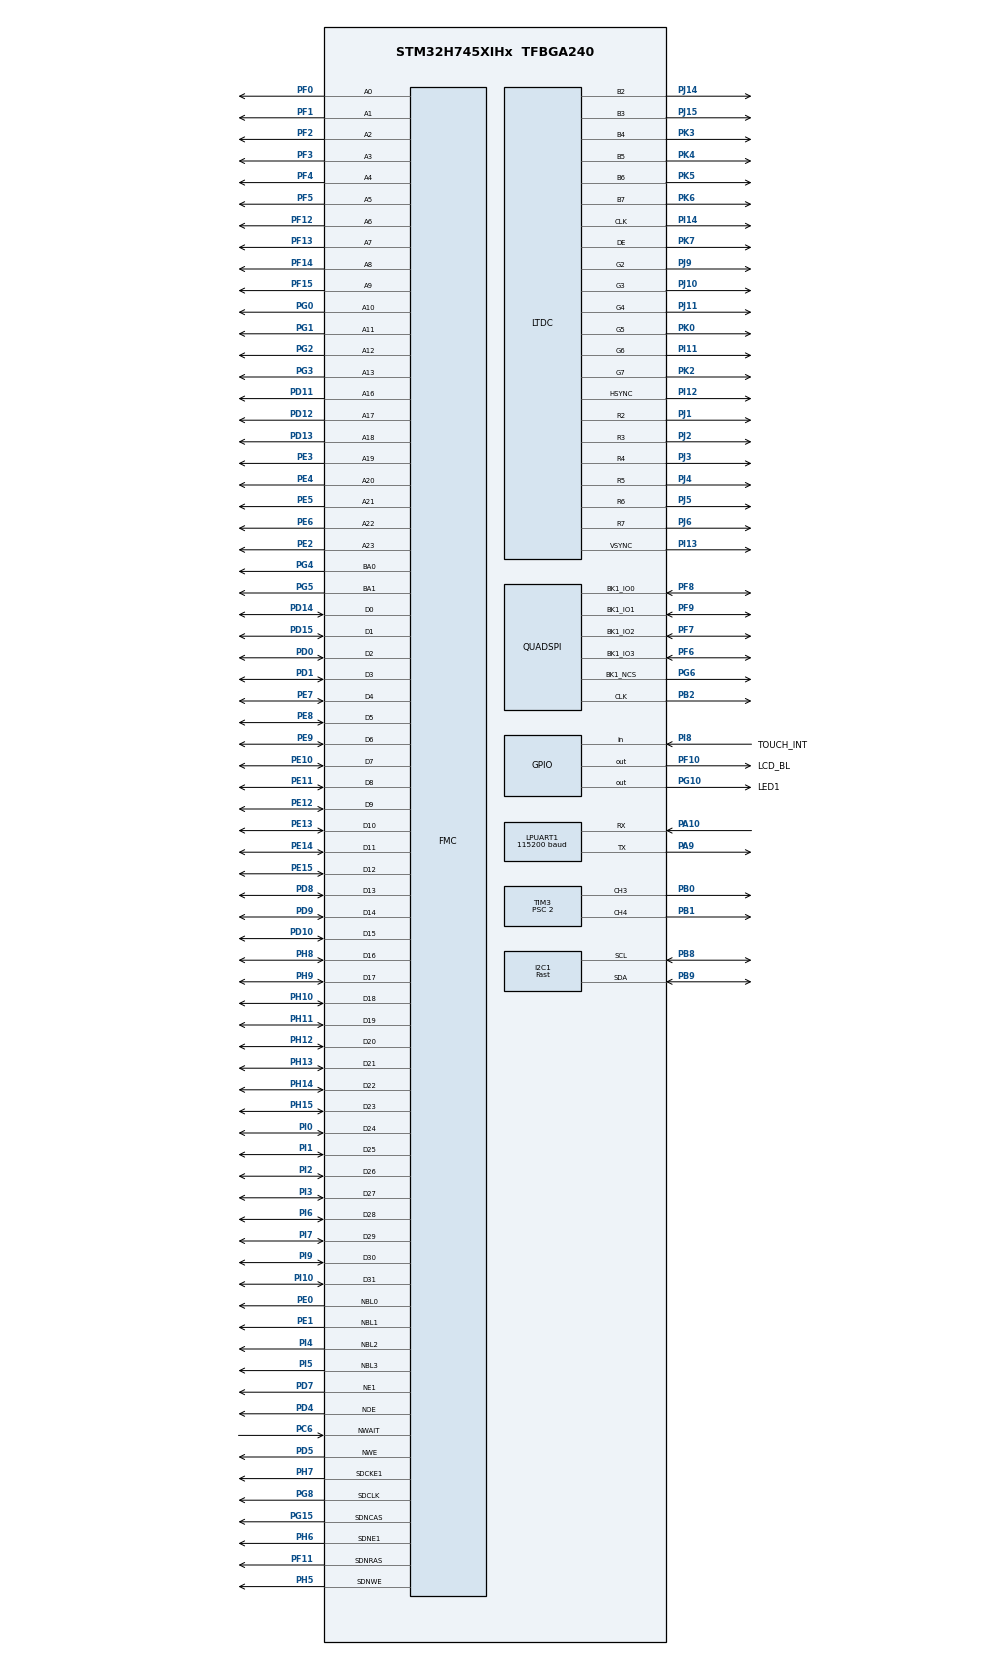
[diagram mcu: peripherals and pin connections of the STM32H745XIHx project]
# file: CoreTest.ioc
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CORTEX_M7.CPU_DCache=Enabled
CORTEX_M7.CPU_ICache=Enabled
CortexM4.IPs=CORTEX_M4\:I,DEBUG,FATFS_M4\:I,FREERTOS_M4\:I,IWDG2\:I,OPENAMP_M4\:I,PDM2PCM_M4\:I,PWR,RCC,RESMGR_UTILITY,SYS_M4\:I,USB_DEVICE_M4\:I,USB_HOST_M4\:I,VREFBUF,WWDG2\:I,DMA,BDMA,MDMA,NVIC2\:I,RTC
CortexM7.IPs=CORTEX_M7\:I,DEBUG\:I,FATFS_M7\:I,FREERTOS_M7\:I,IWDG1\:I,OPENAMP_M7\:I,PDM2PCM_M7\:I,PWR\:I,RCC\:I,RESMGR_UTILITY\:I,SYS\:I,USB_DEVICE_M7\:I,USB_HOST_M7\:I,VREFBUF\:I,WWDG1\:I,DMA\:I,BDMA\:I,MDMA\:I,NVIC1\:I,QUADSPI\:I,I2C1\:I,LPUART1\:I,LTDC\:I,FMC\:I,TIM3\:I,TIM4\:I,RTC\:I,DMA2D\:I
CortexM7.Pins=PG10,PI8,PF10
Dma.Request0=TIM4_CH1
Dma.Request1=TIM4_CH2
Dma.TIM4_CH1.0.Direction=DMA_MEMORY_TO_PERIPH
Dma.TIM4_CH1.0.EventEnable=DISABLE
Dma.TIM4_CH1.0.FIFOMode=DMA_FIFOMODE_DISABLE
Dma.TIM4_CH1.0.Instance=DMA1_Stream0
Dma.TIM4_CH1.0.MemDataAlignment=DMA_MDATAALIGN_WORD
Dma.TIM4_CH1.0.MemInc=DMA_MINC_ENABLE
Dma.TIM4_CH1.0.Mode=DMA_CIRCULAR
Dma.TIM4_CH1.0.PeriphDataAlignment=DMA_PDATAALIGN_WORD
Dma.TIM4_CH1.0.PeriphInc=DMA_PINC_DISABLE
Dma.TIM4_CH1.0.Polarity=HAL_DMAMUX_REQ_GEN_RISING
Dma.TIM4_CH1.0.Priority=DMA_PRIORITY_HIGH
Dma.TIM4_CH1.0.RequestNumber=1
Dma.TIM4_CH1.0.SignalID=NONE
Dma.TIM4_CH1.0.SyncEnable=DISABLE
Dma.TIM4_CH1.0.SyncPolarity=HAL_DMAMUX_SYNC_NO_EVENT
Dma.TIM4_CH1.0.SyncRequestNumber=1
Dma.TIM4_CH1.0.SyncSignalID=NONE
Dma.TIM4_CH2.1.Direction=DMA_MEMORY_TO_PERIPH
Dma.TIM4_CH2.1.EventEnable=DISABLE
Dma.TIM4_CH2.1.FIFOMode=DMA_FIFOMODE_DISABLE
Dma.TIM4_CH2.1.Instance=DMA1_Stream1
Dma.TIM4_CH2.1.MemDataAlignment=DMA_MDATAALIGN_WORD
Dma.TIM4_CH2.1.MemInc=DMA_MINC_ENABLE
Dma.TIM4_CH2.1.Mode=DMA_CIRCULAR
Dma.TIM4_CH2.1.PeriphDataAlignment=DMA_PDATAALIGN_WORD
Dma.TIM4_CH2.1.PeriphInc=DMA_PINC_DISABLE
Dma.TIM4_CH2.1.Polarity=HAL_DMAMUX_REQ_GEN_RISING
Dma.TIM4_CH2.1.Priority=DMA_PRIORITY_HIGH
Dma.TIM4_CH2.1.RequestNumber=1
Dma.TIM4_CH2.1.SignalID=NONE
Dma.TIM4_CH2.1.SyncEnable=DISABLE
Dma.TIM4_CH2.1.SyncPolarity=HAL_DMAMUX_SYNC_NO_EVENT
Dma.TIM4_CH2.1.SyncRequestNumber=1
Dma.TIM4_CH2.1.SyncSignalID=NONE
FMC.AddressSetupTime1=9
FMC.BusTurnAroundDuration1=4
FMC.CASLatency1=FMC_SDRAM_CAS_LATENCY_3
FMC.ColumnBitsNumber1=FMC_SDRAM_COLUMN_BITS_NUM_9
FMC.DataSetupTime1=5
FMC.ExitSelfRefreshDelay1=7
FMC.LoadToActiveDelay1=2
FMC.RCDDelay1=2
FMC.RPDelay1=2
FMC.ReadBurst1=FMC_SDRAM_RBURST_ENABLE
FMC.ReadPipeDelay1=FMC_SDRAM_RPIPE_DELAY_0
FMC.RowCycleDelay1=7
FMC.SDClockPeriod1=FMC_SDRAM_CLOCK_PERIOD_2
FMC.SelfRefreshTime1=4
FMC.WaitSignalPolarity1=FMC_WAIT_SIGNAL_POLARITY_LOW
FMC.WriteOperation1=FMC_WRITE_OPERATION_ENABLE
FMC.WriteRecoveryTime1=4
I2C1.I2C_Speed_Mode=I2C_Fast
I2C1.Timing=0x009034B6
LPUART1.BaudRate=115200
LTDC.ActiveH=480
LTDC.ActiveW=800
LTDC.Alpha_L0=255
LTDC.BlendingFactor1_L0=LTDC_BLENDING_FACTOR1_PAxCA
LTDC.BlendingFactor2_L0=LTDC_BLENDING_FACTOR2_PAxCA
LTDC.Blue_L0=0
LTDC.DEPolarity=LTDC_DEPOLARITY_AL
LTDC.FBStartAdress_L0=0xD0000000
LTDC.Green_L0=0
LTDC.HBP=88
LTDC.HFP=40
LTDC.HSync=48
LTDC.ImageHeight_L0=480
LTDC.ImageWidth_L0=800
LTDC.Layers=0
LTDC.PixelFormat_L0=LTDC_PIXEL_FORMAT_RGB565
LTDC.Red_L0=0
LTDC.VBP=32
LTDC.VFP=13
LTDC.VSync=3
LTDC.WindowX1_L0=800
LTDC.WindowY1_L0=480
Mcu.Family=STM32H7
Mcu.Name=STM32H745XIHx
Mcu.Package=TFBGA240
NVIC1.DMA1_Stream0_IRQn=true\:1\:0\:true\:false\:true\:false\:true
NVIC1.DMA1_Stream1_IRQn=true\:1\:0\:true\:false\:true\:false\:true
NVIC1.HSEM1_IRQn=true\:0\:0\:false\:false\:true\:true\:true
NVIC1.LPUART1_IRQn=true\:3\:0\:true\:false\:true\:true\:true
NVIC1.LTDC_IRQn=true\:0\:0\:false\:false\:true\:true\:true
NVIC1.PriorityGroup=NVIC_PRIORITYGROUP_4
NVIC1.QUADSPI_IRQn=true\:1\:0\:true\:false\:true\:true\:true
NVIC1.TIM3_IRQn=true\:2\:0\:true\:false\:true\:true\:true
NVIC1.TIM4_IRQn=true\:2\:0\:true\:false\:true\:true\:true
NVIC2.HSEM2_IRQn=true\:0\:0\:false\:false\:true\:true\:true
NVIC2.PriorityGroup=NVIC_PRIORITYGROUP_4
PA10.Mode=Asynchronous
PA10.PinAttribute=CortexM7
PA10.Signal=LPUART1_RX
PA13\ (JTMS/SWDIO).Mode=Trace_Asynchronous_SW
PA13\ (JTMS/SWDIO).PinAttribute=CortexM7
PA13\ (JTMS/SWDIO).Signal=DEBUG_JTMS-SWDIO
PA14\ (JTCK/SWCLK).Mode=Trace_Asynchronous_SW
PA14\ (JTCK/SWCLK).PinAttribute=CortexM7
PA14\ (JTCK/SWCLK).Signal=DEBUG_JTCK-SWCLK
PA9.Mode=Asynchronous
PA9.PinAttribute=CortexM7
PA9.Signal=LPUART1_TX
PB0.GPIO_Speed=GPIO_SPEED_FREQ_HIGH
PB0.PinAttribute=CortexM7
PB0.Signal=S_TIM3_CH3
PB1.GPIO_Speed=GPIO_SPEED_FREQ_HIGH
PB1.PinAttribute=CortexM7
PB1.Signal=S_TIM3_CH4
PB2.GPIO_Speed=GPIO_SPEED_FREQ_VERY_HIGH
PB2.Mode=Single Bank 1
PB2.PinAttribute=CortexM7
PB2.Signal=QUADSPI_CLK
PB3\ (JTDO/TRACESWO).Mode=Trace_Asynchronous_SW
PB3\ (JTDO/TRACESWO).PinAttribute=CortexM7
PB3\ (JTDO/TRACESWO).Signal=DEBUG_JTDO-SWO
PB8.Mode=I2C
PB8.PinAttribute=CortexM7
PB8.Signal=I2C1_SCL
PB9.Mode=I2C
PB9.PinAttribute=CortexM7
PB9.Signal=I2C1_SDA
PC14-OSC32_IN\ (OSC32_IN).Mode=LSE-External-Oscillator
PC14-OSC32_IN\ (OSC32_IN).PinAttribute=CortexM7
PC14-OSC32_IN\ (OSC32_IN).Signal=RCC_OSC32_IN
PC15-OSC32_OUT\ (OSC32_OUT).Mode=LSE-External-Oscillator
PC15-OSC32_OUT\ (OSC32_OUT).PinAttribute=CortexM7
PC15-OSC32_OUT\ (OSC32_OUT).Signal=RCC_OSC32_OUT
PC6.PinAttribute=CortexM7
PC6.Signal=FMC_NWAIT
PD0.PinAttribute=CortexM7
PD0.Signal=FMC_D2_DA2
PD1.PinAttribute=CortexM7
PD1.Signal=FMC_D3_DA3
PD10.PinAttribute=CortexM7
PD10.Signal=FMC_D15_DA15
PD11.PinAttribute=CortexM7
PD11.Signal=FMC_A16_CLE
PD12.PinAttribute=CortexM7
PD12.Signal=FMC_A17_ALE
PD13.PinAttribute=CortexM7
PD13.Signal=FMC_A18
PD14.PinAttribute=CortexM7
PD14.Signal=FMC_D0_DA0
PD15.PinAttribute=CortexM7
PD15.Signal=FMC_D1_DA1
PD4.PinAttribute=CortexM7
PD4.Signal=FMC_NOE
PD5.PinAttribute=CortexM7
PD5.Signal=FMC_NWE
PD7.Mode=NorPsramChipSelect1_1
PD7.PinAttribute=CortexM7
PD7.Signal=FMC_NE1
PD8.PinAttribute=CortexM7
PD8.Signal=FMC_D13_DA13
PD9.PinAttribute=CortexM7
PD9.Signal=FMC_D14_DA14
PE0.PinAttribute=CortexM7
PE0.Signal=FMC_NBL0
PE1.PinAttribute=CortexM7
PE1.Signal=FMC_NBL1
PE10.PinAttribute=CortexM7
PE10.Signal=FMC_D7_DA7
PE11.PinAttribute=CortexM7
PE11.Signal=FMC_D8_DA8
PE12.PinAttribute=CortexM7
PE12.Signal=FMC_D9_DA9
PE13.PinAttribute=CortexM7
PE13.Signal=FMC_D10_DA10
PE14.PinAttribute=CortexM7
PE14.Signal=FMC_D11_DA11
PE15.PinAttribute=CortexM7
PE15.Signal=FMC_D12_DA12
PE2.PinAttribute=CortexM7
PE2.Signal=FMC_A23
PE3.PinAttribute=CortexM7
PE3.Signal=FMC_A19
PE4.PinAttribute=CortexM7
PE4.Signal=FMC_A20
PE5.PinAttribute=CortexM7
PE5.Signal=FMC_A21
PE6.PinAttribute=CortexM7
PE6.Signal=FMC_A22
PE7.PinAttribute=CortexM7
PE7.Signal=FMC_D4_DA4
PE8.PinAttribute=CortexM7
PE8.Signal=FMC_D5_DA5
PE9.PinAttribute=CortexM7
PE9.Signal=FMC_D6_DA6
PF0.PinAttribute=CortexM7
PF0.Signal=FMC_A0
PF1.PinAttribute=CortexM7
PF1.Signal=FMC_A1
PF10.GPIO_Label=LCD_BL
PF10.PinAttribute=CortexM7
PF10.Signal=GPIO_Output
PF11.PinAttribute=CortexM7
PF11.Signal=FMC_SDNRAS
PF12.PinAttribute=CortexM7
PF12.Signal=FMC_A6
PF13.PinAttribute=CortexM7
PF13.Signal=FMC_A7
PF14.PinAttribute=CortexM7
PF14.Signal=FMC_A8
PF15.PinAttribute=CortexM7
PF15.Signal=FMC_A9
PF2.PinAttribute=CortexM7
PF2.Signal=FMC_A2
PF3.PinAttribute=CortexM7
PF3.Signal=FMC_A3
PF4.PinAttribute=CortexM7
PF4.Signal=FMC_A4
PF5.PinAttribute=CortexM7
PF5.Signal=FMC_A5
PF6.GPIO_Speed=GPIO_SPEED_FREQ_VERY_HIGH
PF6.Mode=Single Bank 1
PF6.PinAttribute=CortexM7
PF6.Signal=QUADSPI_BK1_IO3
PF7.GPIO_Speed=GPIO_SPEED_FREQ_VERY_HIGH
PF7.Mode=Single Bank 1
PF7.PinAttribute=CortexM7
PF7.Signal=QUADSPI_BK1_IO2
PF8.GPIO_Speed=GPIO_SPEED_FREQ_VERY_HIGH
PF8.Mode=Single Bank 1
PF8.PinAttribute=CortexM7
PF8.Signal=QUADSPI_BK1_IO0
PF9.GPIO_Speed=GPIO_SPEED_FREQ_VERY_HIGH
PF9.Mode=Single Bank 1
PF9.PinAttribute=CortexM7
PF9.Signal=QUADSPI_BK1_IO1
PG0.PinAttribute=CortexM7
PG0.Signal=FMC_A10
PG1.PinAttribute=CortexM7
PG1.Signal=FMC_A11
PG10.GPIO_Label=LED1
PG10.PinAttribute=CortexM7
PG10.Signal=GPIO_Output
PG15.PinAttribute=CortexM7
PG15.Signal=FMC_SDNCAS
PG2.PinAttribute=CortexM7
PG2.Signal=FMC_A12
PG3.PinAttribute=CortexM7
PG3.Signal=FMC_A13
PG4.PinAttribute=CortexM7
PG4.Signal=FMC_A14_BA0
PG5.PinAttribute=CortexM7
PG5.Signal=FMC_A15_BA1
PG6.GPIO_Speed=GPIO_SPEED_FREQ_VERY_HIGH
PG6.Mode=Single Bank 1
PG6.PinAttribute=CortexM7
PG6.Signal=QUADSPI_BK1_NCS
PG8.PinAttribute=CortexM7
PG8.Signal=FMC_SDCLK
PH0-OSC_IN\ (PH0).Mode=HSE-External-Oscillator
PH0-OSC_IN\ (PH0).PinAttribute=CortexM7
PH0-OSC_IN\ (PH0).Signal=RCC_OSC_IN
PH1-OSC_OUT\ (PH1).Mode=HSE-External-Oscillator
PH1-OSC_OUT\ (PH1).PinAttribute=CortexM7
PH1-OSC_OUT\ (PH1).Signal=RCC_OSC_OUT
PH10.PinAttribute=CortexM7
PH10.Signal=FMC_D18
PH11.PinAttribute=CortexM7
PH11.Signal=FMC_D19
PH12.PinAttribute=CortexM7
PH12.Signal=FMC_D20
PH13.PinAttribute=CortexM7
PH13.Signal=FMC_D21
PH14.PinAttribute=CortexM7
PH14.Signal=FMC_D22
PH15.PinAttribute=CortexM7
PH15.Signal=FMC_D23
PH5.PinAttribute=CortexM7
PH5.Signal=FMC_SDNWE
PH6.Mode=SdramChipSelect2_1
PH6.PinAttribute=CortexM7
PH6.Signal=FMC_SDNE1
PH7.Mode=SdramChipSelect2_1
PH7.PinAttribute=CortexM7
PH7.Signal=FMC_SDCKE1
PH8.PinAttribute=CortexM7
PH8.Signal=FMC_D16
PH9.PinAttribute=CortexM7
PH9.Signal=FMC_D17
PI0.PinAttribute=CortexM7
PI0.Signal=FMC_D24
PI1.PinAttribute=CortexM7
PI1.Signal=FMC_D25
PI10.PinAttribute=CortexM7
PI10.Signal=FMC_D31
PI11.Mode=RGB666
PI11.PinAttribute=CortexM7
PI11.Signal=LTDC_G6
PI12.Mode=RGB666
PI12.PinAttribute=CortexM7
PI12.Signal=LTDC_HSYNC
PI13.Mode=RGB666
PI13.PinAttribute=CortexM7
PI13.Signal=LTDC_VSYNC
PI14.Mode=RGB666
PI14.PinAttribute=CortexM7
PI14.Signal=LTDC_CLK
PI2.PinAttribute=CortexM7
PI2.Signal=FMC_D26
PI3.PinAttribute=CortexM7
PI3.Signal=FMC_D27
PI4.PinAttribute=CortexM7
PI4.Signal=FMC_NBL2
PI5.PinAttribute=CortexM7
PI5.Signal=FMC_NBL3
PI6.PinAttribute=CortexM7
PI6.Signal=FMC_D28
PI7.PinAttribute=CortexM7
PI7.Signal=FMC_D29
PI8.GPIO_Label=TOUCH_INT
PI8.PinAttribute=CortexM7
PI8.Signal=GPIO_Input
PI9.PinAttribute=CortexM7
PI9.Signal=FMC_D30
PJ1.Mode=RGB666
PJ1.PinAttribute=CortexM7
PJ1.Signal=LTDC_R2
PJ10.Mode=RGB666
PJ10.PinAttribute=CortexM7
PJ10.Signal=LTDC_G3
PJ11.Mode=RGB666
PJ11.PinAttribute=CortexM7
PJ11.Signal=LTDC_G4
PJ14.Mode=RGB666
PJ14.PinAttribute=CortexM7
PJ14.Signal=LTDC_B2
PJ15.Mode=RGB666
PJ15.PinAttribute=CortexM7
PJ15.Signal=LTDC_B3
PJ2.Mode=RGB666
PJ2.PinAttribute=CortexM7
PJ2.Signal=LTDC_R3
PJ3.Mode=RGB666
PJ3.PinAttribute=CortexM7
PJ3.Signal=LTDC_R4
PJ4.Mode=RGB666
PJ4.PinAttribute=CortexM7
PJ4.Signal=LTDC_R5
PJ5.Mode=RGB666
PJ5.PinAttribute=CortexM7
PJ5.Signal=LTDC_R6
PJ6.Mode=RGB666
PJ6.PinAttribute=CortexM7
PJ6.Signal=LTDC_R7
PJ9.Mode=RGB666
PJ9.PinAttribute=CortexM7
PJ9.Signal=LTDC_G2
PK0.Mode=RGB666
PK0.PinAttribute=CortexM7
PK0.Signal=LTDC_G5
PK2.Mode=RGB666
PK2.PinAttribute=CortexM7
PK2.Signal=LTDC_G7
PK3.Mode=RGB666
PK3.PinAttribute=CortexM7
PK3.Signal=LTDC_B4
PK4.Mode=RGB666
PK4.PinAttribute=CortexM7
PK4.Signal=LTDC_B5
PK5.Mode=RGB666
PK5.PinAttribute=CortexM7
PK5.Signal=LTDC_B6
PK6.Mode=RGB666
PK6.PinAttribute=CortexM7
PK6.Signal=LTDC_B7
PK7.Mode=RGB666
PK7.PinAttribute=CortexM7
PK7.Signal=LTDC_DE
ProjectManager.HeapSize=0x200
ProjectManager.StackSize=0x400
ProjectManager.TargetToolchain=STM32CubeIDE
QUADSPI.ClockPrescaler=4
QUADSPI.FlashSize=25
QUADSPI.SampleShifting=QSPI_SAMPLE_SHIFTING_HALFCYCLE
RCC.ADCFreq_Value=400000000
RCC.APB1Freq_Value=100000000
RCC.APB2Freq_Value=100000000
RCC.APB3Freq_Value=100000000
RCC.APB4Freq_Value=100000000
RCC.CortexFreq_Value=400000000
RCC.D1PPRE=RCC_APB3_DIV2
RCC.D2PPRE1=RCC_APB1_DIV2
RCC.D2PPRE2=RCC_APB2_DIV2
RCC.D3PPRE=RCC_APB4_DIV2
RCC.DIVM1=5
RCC.DIVM2=5
RCC.DIVM3=5
RCC.DIVN1=160
RCC.DIVN2=160
RCC.DIVN3=120
RCC.DIVQ1=4
RCC.DIVR2=8
RCC.DIVR3=20
RCC.FLatency-AdvancedSettings=FLASH_LATENCY_0
RCC.FMCCLockSelection=RCC_FMCCLKSOURCE_PLL2
RCC.HCLKFreq_Value=200000000
RCC.HPRE=RCC_HCLK_DIV2
RCC.PLL1_VCI_Range-AdvancedSettings=RCC_PLL1VCIRANGE_0
RCC.PLL1_VCO_SEL-AdvancedSettings=RCC_PLL1VCOMEDIUM
RCC.PLL3FRACN=0
RCC.PLLFRACN=0
RCC.PLLSourceVirtual=RCC_PLLSOURCE_HSE
RCC.PWR_Regulator_Voltage_Scale=PWR_REGULATOR_VOLTAGE_SCALE0
RCC.QSPICLockSelection=RCC_QSPICLKSOURCE_PLL2
RCC.SYSCLKFreq_VALUE=400000000
RCC.SYSCLKSource=RCC_SYSCLKSOURCE_PLLCLK
RCC.SupplySource=PWR_LDO_SUPPLY
RCC.USBFreq_Value=200000000
SH.FMC_A0.0=FMC_A0,24b-a1
SH.FMC_A0.1=FMC_A0,12b-sda1
SH.FMC_A1.0=FMC_A1,24b-a1
SH.FMC_A1.1=FMC_A1,12b-sda1
SH.FMC_A10.0=FMC_A10,24b-a1
SH.FMC_A10.1=FMC_A10,12b-sda1
SH.FMC_A11.0=FMC_A11,24b-a1
SH.FMC_A11.1=FMC_A11,12b-sda1
SH.FMC_A12.0=FMC_A12,24b-a1
SH.FMC_A13.0=FMC_A13,24b-a1
SH.FMC_A14_BA0.0=FMC_BA0,FourSdramBanks1
SH.FMC_A14_BA0.1=FMC_A14,24b-a1
SH.FMC_A15_BA1.0=FMC_BA1,FourSdramBanks1
SH.FMC_A15_BA1.1=FMC_A15,24b-a1
SH.FMC_A16_CLE.0=FMC_A16,24b-a1
SH.FMC_A17_ALE.0=FMC_A17,24b-a1
SH.FMC_A18.0=FMC_A18,24b-a1
SH.FMC_A19.0=FMC_A19,24b-a1
SH.FMC_A2.0=FMC_A2,24b-a1
SH.FMC_A2.1=FMC_A2,12b-sda1
SH.FMC_A20.0=FMC_A20,24b-a1
SH.FMC_A21.0=FMC_A21,24b-a1
SH.FMC_A22.0=FMC_A22,24b-a1
SH.FMC_A23.0=FMC_A23,24b-a1
SH.FMC_A3.0=FMC_A3,24b-a1
SH.FMC_A3.1=FMC_A3,12b-sda1
SH.FMC_A4.0=FMC_A4,24b-a1
SH.FMC_A4.1=FMC_A4,12b-sda1
SH.FMC_A5.0=FMC_A5,24b-a1
SH.FMC_A5.1=FMC_A5,12b-sda1
SH.FMC_A6.0=FMC_A6,24b-a1
SH.FMC_A6.1=FMC_A6,12b-sda1
SH.FMC_A7.0=FMC_A7,24b-a1
SH.FMC_A7.1=FMC_A7,12b-sda1
SH.FMC_A8.0=FMC_A8,24b-a1
SH.FMC_A8.1=FMC_A8,12b-sda1
SH.FMC_A9.0=FMC_A9,24b-a1
SH.FMC_A9.1=FMC_A9,12b-sda1
SH.FMC_D0_DA0.0=FMC_D0,sd-32b-d1
SH.FMC_D0_DA0.1=FMC_D0,16b-d1
SH.FMC_D10_DA10.0=FMC_D10,sd-32b-d1
SH.FMC_D10_DA10.1=FMC_D10,16b-d1
SH.FMC_D11_DA11.0=FMC_D11,sd-32b-d1
SH.FMC_D11_DA11.1=FMC_D11,16b-d1
SH.FMC_D12_DA12.0=FMC_D12,sd-32b-d1
SH.FMC_D12_DA12.1=FMC_D12,16b-d1
SH.FMC_D13_DA13.0=FMC_D13,sd-32b-d1
SH.FMC_D13_DA13.1=FMC_D13,16b-d1
SH.FMC_D14_DA14.0=FMC_D14,sd-32b-d1
SH.FMC_D14_DA14.1=FMC_D14,16b-d1
SH.FMC_D15_DA15.0=FMC_D15,sd-32b-d1
SH.FMC_D15_DA15.1=FMC_D15,16b-d1
SH.FMC_D16.0=FMC_D16,sd-32b-d1
SH.FMC_D17.0=FMC_D17,sd-32b-d1
SH.FMC_D18.0=FMC_D18,sd-32b-d1
SH.FMC_D19.0=FMC_D19,sd-32b-d1
SH.FMC_D1_DA1.0=FMC_D1,sd-32b-d1
SH.FMC_D1_DA1.1=FMC_D1,16b-d1
SH.FMC_D20.0=FMC_D20,sd-32b-d1
SH.FMC_D21.0=FMC_D21,sd-32b-d1
SH.FMC_D22.0=FMC_D22,sd-32b-d1
SH.FMC_D23.0=FMC_D23,sd-32b-d1
SH.FMC_D24.0=FMC_D24,sd-32b-d1
SH.FMC_D25.0=FMC_D25,sd-32b-d1
SH.FMC_D26.0=FMC_D26,sd-32b-d1
SH.FMC_D27.0=FMC_D27,sd-32b-d1
SH.FMC_D28.0=FMC_D28,sd-32b-d1
SH.FMC_D29.0=FMC_D29,sd-32b-d1
SH.FMC_D2_DA2.0=FMC_D2,sd-32b-d1
SH.FMC_D2_DA2.1=FMC_D2,16b-d1
SH.FMC_D30.0=FMC_D30,sd-32b-d1
SH.FMC_D31.0=FMC_D31,sd-32b-d1
SH.FMC_D3_DA3.0=FMC_D3,sd-32b-d1
SH.FMC_D3_DA3.1=FMC_D3,16b-d1
SH.FMC_D4_DA4.0=FMC_D4,sd-32b-d1
SH.FMC_D4_DA4.1=FMC_D4,16b-d1
SH.FMC_D5_DA5.0=FMC_D5,sd-32b-d1
SH.FMC_D5_DA5.1=FMC_D5,16b-d1
SH.FMC_D6_DA6.0=FMC_D6,sd-32b-d1
SH.FMC_D6_DA6.1=FMC_D6,16b-d1
SH.FMC_D7_DA7.0=FMC_D7,sd-32b-d1
SH.FMC_D7_DA7.1=FMC_D7,16b-d1
SH.FMC_D8_DA8.0=FMC_D8,sd-32b-d1
SH.FMC_D8_DA8.1=FMC_D8,16b-d1
SH.FMC_D9_DA9.0=FMC_D9,sd-32b-d1
SH.FMC_D9_DA9.1=FMC_D9,16b-d1
SH.FMC_NBL0.0=FMC_NBL0,Sd4ByteEnable1
SH.FMC_NBL1.0=FMC_NBL1,Sd4ByteEnable1
SH.FMC_NBL2.0=FMC_NBL2,Sd4ByteEnable1
SH.FMC_NBL3.0=FMC_NBL3,Sd4ByteEnable1
SH.FMC_NOE.0=FMC_NOE,NorFlash1
SH.FMC_NWAIT.0=FMC_NWAIT,AsynchronousWait1
SH.FMC_NWE.0=FMC_NWE,NorFlash1
SH.FMC_SDCLK.0=FMC_SDCLK,12b-sda1
SH.FMC_SDNCAS.0=FMC_SDNCAS,12b-sda1
SH.FMC_SDNRAS.0=FMC_SDNRAS,12b-sda1
SH.FMC_SDNWE.0=FMC_SDNWE,12b-sda1
SH.S_TIM3_CH3.0=TIM3_CH3,PWM Generation3 CH3
SH.S_TIM3_CH4.0=TIM3_CH4,PWM Generation4 CH4
SYS.userName=SYS_M7
TIM3.AutoReloadPreload=TIM_AUTORELOAD_PRELOAD_ENABLE
TIM3.Channel-PWM\ Generation3\ CH3=TIM_CHANNEL_3
TIM3.Channel-PWM\ Generation4\ CH4=TIM_CHANNEL_4
TIM3.Period=1023
TIM3.Prescaler=2
TIM4.AutoReloadPreload=TIM_AUTORELOAD_PRELOAD_ENABLE
TIM4.Channel-Output\ Compare1\ No\ Output=TIM_CHANNEL_1
TIM4.Channel-Output\ Compare2\ No\ Output=TIM_CHANNEL_2
TIM4.Period=99
TIM4.Prescaler=2
VP_DMA2D_VS_DMA2D.Mode=DMA2D_Activate
VP_RTC_VS_RTC_Activate.Mode=RTC_Enabled
VP_SYS_M4_VS_Systick.Mode=SysTick
VP_TIM3_VS_ClockSourceINT.Mode=Internal
VP_TIM4_VS_ClockSourceINT.Mode=Internal
VP_TIM4_VS_no_output1.Mode=Output Compare1 No Output
VP_TIM4_VS_no_output2.Mode=Output Compare2 No Output
board=custom

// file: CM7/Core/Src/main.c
/* USER CODE BEGIN Header */
/**
  ******************************************************************************
  * @file           : main.c
  * @brief          : Main program body
  ******************************************************************************
  * @attention
  *
  * <h2><center>&copy; Copyright (c) 2021 STMicroelectronics.
  * All rights reserved.</center></h2>
  *
  * This software component is licensed by ST under BSD 3-Clause license,
  * the "License"; You may not use this file except in compliance with the
  * License. You may obtain a copy of the License at:
  *                        opensource.org/licenses/BSD-3-Clause
  *
  ******************************************************************************
  */
/* USER CODE END Header */
#include "main.h"

/* USER CODE BEGIN Includes */
#include <stdio.h>
#include <string.h>

#include "sdram.h"
#include "quadspi.h"
#include "nor.h"
#include "beep.h"
#include "serial.h"
#include "shell.h"

#include "lwshell/lwshell.h"
/* USER CODE END Includes */

/* USER CODE BEGIN PD */

#ifndef HSEM_ID_0
#define HSEM_ID_0 (0U) /* HW semaphore 0*/
#endif

#ifndef HSEM_ID_1
#define HSEM_ID_1 (1U) /* HW semaphore 1*/
#endif

/* USER CODE END PD */

/* USER CODE BEGIN PM */

#define ENABLE_QSPI_TEST				(1)
#define ENABLE_SDRAM_TEST				(1)
#define ENABLE_NOR_TEST					(1)

#define PWR_WAKEUP_FLAGS  (PWR_WAKEUP_FLAG1 | PWR_WAKEUP_FLAG2 | PWR_WAKEUP_FLAG3 | \
                           PWR_WAKEUP_FLAG4 | PWR_WAKEUP_FLAG5 | PWR_WAKEUP_FLAG6)

/* USER CODE END PM */

DMA2D_HandleTypeDef hdma2d;

I2C_HandleTypeDef hi2c1;

UART_HandleTypeDef hlpuart1;

LTDC_HandleTypeDef hltdc;

QSPI_HandleTypeDef hqspi;

RTC_HandleTypeDef hrtc;

TIM_HandleTypeDef htim3;
TIM_HandleTypeDef htim4;
DMA_HandleTypeDef hdma_tim4_ch1;
DMA_HandleTypeDef hdma_tim4_ch2;

NOR_HandleTypeDef hnor1;
SDRAM_HandleTypeDef hsdram1;

void SystemClock_Config(void);
void PeriphCommonClock_Config(void);
static void MX_GPIO_Init(void);
static void MX_DMA_Init(void);
static void MX_FMC_Init(void);
static void MX_QUADSPI_Init(void);
static void MX_LPUART1_UART_Init(void);
static void MX_I2C1_Init(void);
static void MX_LTDC_Init(void);
static void MX_TIM3_Init(void);
static void MX_TIM4_Init(void);
static void MX_RTC_Init(void);
static void MX_DMA2D_Init(void);
/* USER CODE BEGIN PFP */
static void MPU_Config(void);
/* USER CODE END PFP */

/* USER CODE BEGIN 0 */
//int __io_putchar(int ch)
//{
//	//HAL_UART_Transmit(&hlpuart1, (uint8_t *)&ch, 1, 100);
//	serial_write(ch);
//	return 1;
//}
int _write(int file, char *ptr, int len)
{
	for (int i = 0; i < len; i++)
		serial_write(ptr[i]);

	return len;
}
/* USER CODE END 0 */

int main(void)
{
  /* USER CODE BEGIN 1 */
#if ENABLE_NOR_TEST || 1
	MPU_Config();
#endif
  /* USER CODE END 1 */
/* USER CODE BEGIN Boot_Mode_Sequence_0 */
  int32_t timeout;
/* USER CODE END Boot_Mode_Sequence_0 */

  /* Enable I-Cache---------------------------------------------------------*/
  SCB_EnableICache();

  /* Enable D-Cache---------------------------------------------------------*/
  SCB_EnableDCache();

/* USER CODE BEGIN Boot_Mode_Sequence_1 */
  /* Wait until CPU2 boots and enters in stop mode or timeout*/
  timeout = 0xFFFF;
  while((__HAL_RCC_GET_FLAG(RCC_FLAG_D2CKRDY) != RESET) && (timeout-- > 0));
  if ( timeout < 0 )
  {
	  Error_Handler();
  }
/* USER CODE END Boot_Mode_Sequence_1 */
  /* MCU Configuration--------------------------------------------------------*/

  /* Reset of all peripherals, Initializes the Flash interface and the Systick. */
  HAL_Init();

  /* Configure the system clock */
  SystemClock_Config();

	/* Configure the peripherals common clocks */
	  PeriphCommonClock_Config();
	/* USER CODE BEGIN Boot_Mode_Sequence_2 */
	/* When system initialization is finished, Cortex-M7 will release Cortex-M4 by means of
	HSEM notification */
	/*HW semaphore Clock enable*/
	__HAL_RCC_HSEM_CLK_ENABLE();
	/*Take HSEM */
	HAL_HSEM_FastTake(HSEM_ID_0);
	/*Release HSEM in order to notify the CPU2(CM4)*/
	HAL_HSEM_Release(HSEM_ID_0,0);
	/* wait until CPU2 wakes up from stop mode */
	timeout = 0xFFFF;
	while((__HAL_RCC_GET_FLAG(RCC_FLAG_D2CKRDY) == RESET) && (timeout-- > 0));
	if ( timeout < 0 )
	{
		Error_Handler();
	}
	/* USER CODE END Boot_Mode_Sequence_2 */

  /* USER CODE BEGIN SysInit */

	/* Check and handle if the system was resumed from StandBy mode */
	if(__HAL_PWR_GET_FLAG(PWR_FLAG_SB) != RESET)
	{
	  /* Clear system Standby flag */
	  __HAL_PWR_CLEAR_FLAG(PWR_FLAG_SB);
	}

  /* USER CODE END SysInit */

  /* Initialize all configured peripherals */
  MX_GPIO_Init();
  MX_DMA_Init();
  MX_FMC_Init();
  MX_QUADSPI_Init();
  MX_LPUART1_UART_Init();
  MX_I2C1_Init();
  MX_LTDC_Init();
  MX_TIM3_Init();
  MX_TIM4_Init();
  MX_RTC_Init();
  MX_DMA2D_Init();
  /* USER CODE BEGIN 2 */

  serial_init(&hlpuart1);

#if 0
  /* The Following Wakeup sequence is highly recommended prior to each Standby mode entry
    mainly  when using more than one wakeup source this is to not miss any wakeup event.
    - Disable all used wakeup sources,
    - Clear all related wakeup flags,
    - Re-enable all used wakeup sources,
    - Enter the Standby mode.
  */
  /* Disable all used wakeup sources*/
  HAL_PWREx_DisableWakeUpPin(PWR_WAKEUP_PIN4);

  /* Re-enable all used wakeup sources*/
  /* Configure Wakeup pin */
  PWREx_WakeupPinTypeDef sPinParams;
  sPinParams.WakeUpPin    = PWR_WAKEUP_PIN4;
  sPinParams.PinPolarity  = PWR_PIN_POLARITY_LOW;
  sPinParams.PinPull      = PWR_PIN_NO_PULL;
  HAL_PWREx_EnableWakeUpPin(&sPinParams);

  /* Clear all related wakeup flags */
  HAL_StatusTypeDef ret = HAL_PWREx_ClearWakeupFlag(PWR_WAKEUP_FLAGS);
  if(ret != HAL_OK)
  {
    Error_Handler();
  }
#endif

  /* USER CODE END 2 */

  /* Infinite loop */
  /* USER CODE BEGIN WHILE */

  //
  uint32_t count = 0;
  while (count++ < 10)
  {
	  HAL_GPIO_TogglePin(LED1_GPIO_Port, LED1_Pin);
	  HAL_Delay(100);
  }
  // turn-off
  HAL_GPIO_WritePin(LED1_GPIO_Port, LED1_Pin, GPIO_PIN_SET);
  printf("STM32H745 CoreBoard....\r\n");

  beep_init();
  shell_init();

#if DEPRECATED || 1
  uint32_t tone[] = { 240, 320, 470, 0, 600, 0 };
  uint32_t delay[] = { 200, 200, 200, 100, 400, 100 };
#if 0
  uint32_t tick = HAL_GetTick();
  int i = 0;
  beep_setFreq(tone[i]);
#else
  for (int i = 0; i < sizeof(tone) / sizeof(tone[0]); i++)
  {
	  beep_setFreq(tone[i]);
	  HAL_Delay(delay[i]);
  }
#endif
#endif

  uint32_t blinkTick = HAL_GetTick();
  int blinkType = 0;

  HAL_GPIO_WritePin(LCD_BL_GPIO_Port, LCD_BL_Pin, GPIO_PIN_SET);

  //
  volatile unsigned char* lcd = (volatile unsigned char *)(0xD0000000);
  for (int i = 0; i < 800 * 480 / 3; i++ )
  {
	  *lcd++ = 0xF8;
	  *lcd++ = 0x00;
  }
  for (int i = 0; i < 800 * 480 / 3; i++ )
  {
	  *lcd++ = 0x07;
	  *lcd++ = 0xE0;
  }
  for (int i = 0; i < 800 * 480 / 3; i++ )
  {
	  *lcd++ = 0x00;
	  *lcd++ = 0x1F;
  }

  while (1)
  {
	  shell_process();

#if DEPRECATED || 0
	  if (HAL_GetTick() - tick > delay[i])
	  {
		  tick = HAL_GetTick();

		  i = (i + 1) % (sizeof(delay) / sizeof(delay[0]));
		  if (tone[i])
			  beep_setFreq(tone[i]);
		  else
			  beep_mute();
		  //printf("beep %d Hz   %ld\r\n", (int)tone[i], tick);
	  }
#endif
    /* USER CODE END WHILE */

    /* USER CODE BEGIN 3 */
	  uint32_t blinkDelay = (blinkType == 0) ? 800 : 200;
	  if (HAL_GetTick() - blinkTick > blinkDelay)
	  {
		  blinkTick = HAL_GetTick();
		  HAL_GPIO_TogglePin(LED1_GPIO_Port, LED1_Pin);
		  blinkType = (1 - blinkType);
	  }
  }
  /* USER CODE END 3 */
}

void SystemClock_Config(void)
{
  RCC_OscInitTypeDef RCC_OscInitStruct = {0};
  RCC_ClkInitTypeDef RCC_ClkInitStruct = {0};

  /** Supply configuration update enable
  */
  HAL_PWREx_ConfigSupply(PWR_LDO_SUPPLY);
  /** Configure the main internal regulator output voltage
  */
  __HAL_PWR_VOLTAGESCALING_CONFIG(PWR_REGULATOR_VOLTAGE_SCALE0);

  while(!__HAL_PWR_GET_FLAG(PWR_FLAG_VOSRDY)) {}
  /** Macro to configure the PLL clock source
  */
  __HAL_RCC_PLL_PLLSOURCE_CONFIG(RCC_PLLSOURCE_HSE);
  /** Initializes the RCC Oscillators according to the specified parameters
  * in the RCC_OscInitTypeDef structure.
  */
  RCC_OscInitStruct.OscillatorType = RCC_OSCILLATORTYPE_LSI|RCC_OSCILLATORTYPE_HSE;
  RCC_OscInitStruct.HSEState = RCC_HSE_ON;
  RCC_OscInitStruct.LSIState = RCC_LSI_ON;
  RCC_OscInitStruct.PLL.PLLState = RCC_PLL_ON;
  RCC_OscInitStruct.PLL.PLLSource = RCC_PLLSOURCE_HSE;
  RCC_OscInitStruct.PLL.PLLM = 5;
  RCC_OscInitStruct.PLL.PLLN = 160;
  RCC_OscInitStruct.PLL.PLLP = 2;
  RCC_OscInitStruct.PLL.PLLQ = 4;
  RCC_OscInitStruct.PLL.PLLR = 2;
  RCC_OscInitStruct.PLL.PLLRGE = RCC_PLL1VCIRANGE_2;
  RCC_OscInitStruct.PLL.PLLVCOSEL = RCC_PLL1VCOWIDE;
  RCC_OscInitStruct.PLL.PLLFRACN = 0;
  if (HAL_RCC_OscConfig(&RCC_OscInitStruct) != HAL_OK)
  {
    Error_Handler();
  }
  /** Initializes the CPU, AHB and APB buses clocks
  */
  RCC_ClkInitStruct.ClockType = RCC_CLOCKTYPE_HCLK|RCC_CLOCKTYPE_SYSCLK
                              |RCC_CLOCKTYPE_PCLK1|RCC_CLOCKTYPE_PCLK2
                              |RCC_CLOCKTYPE_D3PCLK1|RCC_CLOCKTYPE_D1PCLK1;
  RCC_ClkInitStruct.SYSCLKSource = RCC_SYSCLKSOURCE_PLLCLK;
  RCC_ClkInitStruct.SYSCLKDivider = RCC_SYSCLK_DIV1;
  RCC_ClkInitStruct.AHBCLKDivider = RCC_HCLK_DIV2;
  RCC_ClkInitStruct.APB3CLKDivider = RCC_APB3_DIV2;
  RCC_ClkInitStruct.APB1CLKDivider = RCC_APB1_DIV2;
  RCC_ClkInitStruct.APB2CLKDivider = RCC_APB2_DIV2;
  RCC_ClkInitStruct.APB4CLKDivider = RCC_APB4_DIV2;

  if (HAL_RCC_ClockConfig(&RCC_ClkInitStruct, FLASH_LATENCY_2) != HAL_OK)
  {
    Error_Handler();
  }
}

void PeriphCommonClock_Config(void)
{
  RCC_PeriphCLKInitTypeDef PeriphClkInitStruct = {0};

  /** Initializes the peripherals clock
  */
  PeriphClkInitStruct.PeriphClockSelection = RCC_PERIPHCLK_FMC|RCC_PERIPHCLK_QSPI;
  PeriphClkInitStruct.PLL2.PLL2M = 5;
  PeriphClkInitStruct.PLL2.PLL2N = 160;
  PeriphClkInitStruct.PLL2.PLL2P = 2;
  PeriphClkInitStruct.PLL2.PLL2Q = 2;
  PeriphClkInitStruct.PLL2.PLL2R = 8;
  PeriphClkInitStruct.PLL2.PLL2RGE = RCC_PLL2VCIRANGE_2;
  PeriphClkInitStruct.PLL2.PLL2VCOSEL = RCC_PLL2VCOWIDE;
  PeriphClkInitStruct.PLL2.PLL2FRACN = 0;
  PeriphClkInitStruct.FmcClockSelection = RCC_FMCCLKSOURCE_PLL2;
  PeriphClkInitStruct.QspiClockSelection = RCC_QSPICLKSOURCE_PLL2;
  if (HAL_RCCEx_PeriphCLKConfig(&PeriphClkInitStruct) != HAL_OK)
  {
    Error_Handler();
  }
}

static void MX_DMA2D_Init(void)
{

  hdma2d.Instance = DMA2D;
  hdma2d.Init.Mode = DMA2D_M2M;
  hdma2d.Init.ColorMode = DMA2D_OUTPUT_ARGB8888;
  hdma2d.Init.OutputOffset = 0;
  hdma2d.LayerCfg[1].InputOffset = 0;
  hdma2d.LayerCfg[1].InputColorMode = DMA2D_INPUT_ARGB8888;
  hdma2d.LayerCfg[1].AlphaMode = DMA2D_NO_MODIF_ALPHA;
  hdma2d.LayerCfg[1].InputAlpha = 0;
  hdma2d.LayerCfg[1].AlphaInverted = DMA2D_REGULAR_ALPHA;
  hdma2d.LayerCfg[1].RedBlueSwap = DMA2D_RB_REGULAR;
  hdma2d.LayerCfg[1].ChromaSubSampling = DMA2D_NO_CSS;
  if (HAL_DMA2D_Init(&hdma2d) != HAL_OK)
  {
    Error_Handler();
  }
  if (HAL_DMA2D_ConfigLayer(&hdma2d, 1) != HAL_OK)
  {
    Error_Handler();
  }

}

static void MX_I2C1_Init(void)
{

  hi2c1.Instance = I2C1;
  hi2c1.Init.Timing = 0x009034B6;
  hi2c1.Init.OwnAddress1 = 0;
  hi2c1.Init.AddressingMode = I2C_ADDRESSINGMODE_7BIT;
  hi2c1.Init.DualAddressMode = I2C_DUALADDRESS_DISABLE;
  hi2c1.Init.OwnAddress2 = 0;
  hi2c1.Init.OwnAddress2Masks = I2C_OA2_NOMASK;
  hi2c1.Init.GeneralCallMode = I2C_GENERALCALL_DISABLE;
  hi2c1.Init.NoStretchMode = I2C_NOSTRETCH_DISABLE;
  if (HAL_I2C_Init(&hi2c1) != HAL_OK)
  {
    Error_Handler();
  }
  /** Configure Analogue filter
  */
  if (HAL_I2CEx_ConfigAnalogFilter(&hi2c1, I2C_ANALOGFILTER_ENABLE) != HAL_OK)
  {
    Error_Handler();
  }
  /** Configure Digital filter
  */
  if (HAL_I2CEx_ConfigDigitalFilter(&hi2c1, 0) != HAL_OK)
  {
    Error_Handler();
  }

}

static void MX_LPUART1_UART_Init(void)
{

  hlpuart1.Instance = LPUART1;
  hlpuart1.Init.BaudRate = 115200;
  hlpuart1.Init.WordLength = UART_WORDLENGTH_8B;
  hlpuart1.Init.StopBits = UART_STOPBITS_1;
  hlpuart1.Init.Parity = UART_PARITY_NONE;
  hlpuart1.Init.Mode = UART_MODE_TX_RX;
  hlpuart1.Init.HwFlowCtl = UART_HWCONTROL_NONE;
  hlpuart1.Init.OneBitSampling = UART_ONE_BIT_SAMPLE_DISABLE;
  hlpuart1.Init.ClockPrescaler = UART_PRESCALER_DIV1;
  hlpuart1.AdvancedInit.AdvFeatureInit = UART_ADVFEATURE_NO_INIT;
  hlpuart1.FifoMode = UART_FIFOMODE_DISABLE;
  if (HAL_UART_Init(&hlpuart1) != HAL_OK)
  {
    Error_Handler();
  }
  if (HAL_UARTEx_SetTxFifoThreshold(&hlpuart1, UART_TXFIFO_THRESHOLD_1_8) != HAL_OK)
  {
    Error_Handler();
  }
  if (HAL_UARTEx_SetRxFifoThreshold(&hlpuart1, UART_RXFIFO_THRESHOLD_1_8) != HAL_OK)
  {
    Error_Handler();
  }
  if (HAL_UARTEx_DisableFifoMode(&hlpuart1) != HAL_OK)
  {
    Error_Handler();
  }

}

static void MX_LTDC_Init(void)
{

  LTDC_LayerCfgTypeDef pLayerCfg = {0};

  hltdc.Instance = LTDC;
  hltdc.Init.HSPolarity = LTDC_HSPOLARITY_AL;
  hltdc.Init.VSPolarity = LTDC_VSPOLARITY_AL;
  hltdc.Init.DEPolarity = LTDC_VSPOLARITY_AL;
  hltdc.Init.PCPolarity = LTDC_PCPOLARITY_IPC;
  hltdc.Init.HorizontalSync = 88;
  hltdc.Init.VerticalSync = 32;
  hltdc.Init.AccumulatedHBP = 135;
  hltdc.Init.AccumulatedVBP = 34;
  hltdc.Init.AccumulatedActiveW = 935;
  hltdc.Init.AccumulatedActiveH = 514;
  hltdc.Init.TotalWidth = 975;
  hltdc.Init.TotalHeigh = 527;
  hltdc.Init.Backcolor.Blue = 0;
  hltdc.Init.Backcolor.Green = 0;
  hltdc.Init.Backcolor.Red = 0;
  if (HAL_LTDC_Init(&hltdc) != HAL_OK)
  {
    Error_Handler();
  }
  pLayerCfg.WindowX0 = 0;
  pLayerCfg.WindowX1 = 800;
  pLayerCfg.WindowY0 = 0;
  pLayerCfg.WindowY1 = 480;
  pLayerCfg.PixelFormat = LTDC_PIXEL_FORMAT_RGB565;
  pLayerCfg.Alpha = 255;
  pLayerCfg.Alpha0 = 0;
  pLayerCfg.BlendingFactor1 = LTDC_BLENDING_FACTOR1_PAxCA;
  pLayerCfg.BlendingFactor2 = LTDC_BLENDING_FACTOR2_PAxCA;
  pLayerCfg.FBStartAdress = 0xD0000000;
  pLayerCfg.ImageWidth = 800;
  pLayerCfg.ImageHeight = 480;
  pLayerCfg.Backcolor.Blue = 0;
  pLayerCfg.Backcolor.Green = 0;
  pLayerCfg.Backcolor.Red = 0;
  if (HAL_LTDC_ConfigLayer(&hltdc, &pLayerCfg, 0) != HAL_OK)
  {
    Error_Handler();
  }

}

static void MX_QUADSPI_Init(void)
{

  /* QUADSPI parameter configuration*/
  hqspi.Instance = QUADSPI;
  hqspi.Init.ClockPrescaler = 4;
  hqspi.Init.FifoThreshold = 1;
  hqspi.Init.SampleShifting = QSPI_SAMPLE_SHIFTING_HALFCYCLE;
  hqspi.Init.FlashSize = 25;
  hqspi.Init.ChipSelectHighTime = QSPI_CS_HIGH_TIME_1_CYCLE;
  hqspi.Init.ClockMode = QSPI_CLOCK_MODE_0;
  hqspi.Init.FlashID = QSPI_FLASH_ID_1;
  hqspi.Init.DualFlash = QSPI_DUALFLASH_DISABLE;
  if (HAL_QSPI_Init(&hqspi) != HAL_OK)
  {
    Error_Handler();
  }

}

static void MX_RTC_Init(void)
{

  /** Initialize RTC Only
  */
  hrtc.Instance = RTC;
  hrtc.Init.HourFormat = RTC_HOURFORMAT_24;
  hrtc.Init.AsynchPrediv = 127;
  hrtc.Init.SynchPrediv = 255;
  hrtc.Init.OutPut = RTC_OUTPUT_DISABLE;
  hrtc.Init.OutPutPolarity = RTC_OUTPUT_POLARITY_HIGH;
  hrtc.Init.OutPutType = RTC_OUTPUT_TYPE_OPENDRAIN;
  hrtc.Init.OutPutRemap = RTC_OUTPUT_REMAP_NONE;
  if (HAL_RTC_Init(&hrtc) != HAL_OK)
  {
    Error_Handler();
  }

}

static void MX_TIM3_Init(void)
{

  TIM_ClockConfigTypeDef sClockSourceConfig = {0};
  TIM_MasterConfigTypeDef sMasterConfig = {0};
  TIM_OC_InitTypeDef sConfigOC = {0};

  htim3.Instance = TIM3;
  htim3.Init.Prescaler = 2;
  htim3.Init.CounterMode = TIM_COUNTERMODE_UP;
  htim3.Init.Period = 1023;
  htim3.Init.ClockDivision = TIM_CLOCKDIVISION_DIV1;
  htim3.Init.AutoReloadPreload = TIM_AUTORELOAD_PRELOAD_ENABLE;
  if (HAL_TIM_Base_Init(&htim3) != HAL_OK)
  {
    Error_Handler();
  }
  sClockSourceConfig.ClockSource = TIM_CLOCKSOURCE_INTERNAL;
  if (HAL_TIM_ConfigClockSource(&htim3, &sClockSourceConfig) != HAL_OK)
  {
    Error_Handler();
  }
  if (HAL_TIM_PWM_Init(&htim3) != HAL_OK)
  {
    Error_Handler();
  }
  sMasterConfig.MasterOutputTrigger = TIM_TRGO_RESET;
  sMasterConfig.MasterSlaveMode = TIM_MASTERSLAVEMODE_DISABLE;
  if (HAL_TIMEx_MasterConfigSynchronization(&htim3, &sMasterConfig) != HAL_OK)
  {
    Error_Handler();
  }
  sConfigOC.OCMode = TIM_OCMODE_PWM1;
  sConfigOC.Pulse = 0;
  sConfigOC.OCPolarity = TIM_OCPOLARITY_HIGH;
  sConfigOC.OCFastMode = TIM_OCFAST_DISABLE;
  if (HAL_TIM_PWM_ConfigChannel(&htim3, &sConfigOC, TIM_CHANNEL_3) != HAL_OK)
  {
    Error_Handler();
  }
  if (HAL_TIM_PWM_ConfigChannel(&htim3, &sConfigOC, TIM_CHANNEL_4) != HAL_OK)
  {
    Error_Handler();
  }
  HAL_TIM_MspPostInit(&htim3);

}

static void MX_TIM4_Init(void)
{

  TIM_ClockConfigTypeDef sClockSourceConfig = {0};
  TIM_MasterConfigTypeDef sMasterConfig = {0};
  TIM_OC_InitTypeDef sConfigOC = {0};

  htim4.Instance = TIM4;
  htim4.Init.Prescaler = 2;
  htim4.Init.CounterMode = TIM_COUNTERMODE_UP;
  htim4.Init.Period = 99;
  htim4.Init.ClockDivision = TIM_CLOCKDIVISION_DIV1;
  htim4.Init.AutoReloadPreload = TIM_AUTORELOAD_PRELOAD_ENABLE;
  if (HAL_TIM_Base_Init(&htim4) != HAL_OK)
  {
    Error_Handler();
  }
  sClockSourceConfig.ClockSource = TIM_CLOCKSOURCE_INTERNAL;
  if (HAL_TIM_ConfigClockSource(&htim4, &sClockSourceConfig) != HAL_OK)
  {
    Error_Handler();
  }
  if (HAL_TIM_OC_Init(&htim4) != HAL_OK)
  {
    Error_Handler();
  }
  sMasterConfig.MasterOutputTrigger = TIM_TRGO_RESET;
  sMasterConfig.MasterSlaveMode = TIM_MASTERSLAVEMODE_DISABLE;
  if (HAL_TIMEx_MasterConfigSynchronization(&htim4, &sMasterConfig) != HAL_OK)
  {
    Error_Handler();
  }
  sConfigOC.OCMode = TIM_OCMODE_TIMING;
  sConfigOC.Pulse = 0;
  sConfigOC.OCPolarity = TIM_OCPOLARITY_HIGH;
  sConfigOC.OCFastMode = TIM_OCFAST_DISABLE;
  if (HAL_TIM_OC_ConfigChannel(&htim4, &sConfigOC, TIM_CHANNEL_1) != HAL_OK)
  {
    Error_Handler();
  }
  if (HAL_TIM_OC_ConfigChannel(&htim4, &sConfigOC, TIM_CHANNEL_2) != HAL_OK)
  {
    Error_Handler();
  }

}

static void MX_DMA_Init(void)
{

  /* DMA controller clock enable */
  __HAL_RCC_DMA1_CLK_ENABLE();

  /* DMA interrupt init */
  /* DMA1_Stream0_IRQn interrupt configuration */
  HAL_NVIC_SetPriority(DMA1_Stream0_IRQn, 1, 0);
  HAL_NVIC_EnableIRQ(DMA1_Stream0_IRQn);
  /* DMA1_Stream1_IRQn interrupt configuration */
  HAL_NVIC_SetPriority(DMA1_Stream1_IRQn, 1, 0);
  HAL_NVIC_EnableIRQ(DMA1_Stream1_IRQn);

}

/* FMC initialization function */
void MX_FMC_Init(void)
{

  FMC_NORSRAM_TimingTypeDef Timing = {0};
  FMC_SDRAM_TimingTypeDef SdramTiming = {0};

  /** Perform the NOR1 memory initialization sequence
  */
  hnor1.Instance = FMC_NORSRAM_DEVICE;
  hnor1.Extended = FMC_NORSRAM_EXTENDED_DEVICE;
  /* hnor1.Init */
  hnor1.Init.NSBank = FMC_NORSRAM_BANK1;
  hnor1.Init.DataAddressMux = FMC_DATA_ADDRESS_MUX_DISABLE;
  hnor1.Init.MemoryType = FMC_MEMORY_TYPE_NOR;
  hnor1.Init.MemoryDataWidth = FMC_NORSRAM_MEM_BUS_WIDTH_16;
  hnor1.Init.BurstAccessMode = FMC_BURST_ACCESS_MODE_DISABLE;
  hnor1.Init.WaitSignalPolarity = FMC_WAIT_SIGNAL_POLARITY_LOW;
  hnor1.Init.WaitSignalActive = FMC_WAIT_TIMING_BEFORE_WS;
  hnor1.Init.WriteOperation = FMC_WRITE_OPERATION_ENABLE;
  hnor1.Init.WaitSignal = FMC_WAIT_SIGNAL_DISABLE;
  hnor1.Init.ExtendedMode = FMC_EXTENDED_MODE_DISABLE;
  hnor1.Init.AsynchronousWait = FMC_ASYNCHRONOUS_WAIT_ENABLE;
  hnor1.Init.WriteBurst = FMC_WRITE_BURST_DISABLE;
  hnor1.Init.ContinuousClock = FMC_CONTINUOUS_CLOCK_SYNC_ONLY;
  hnor1.Init.WriteFifo = FMC_WRITE_FIFO_ENABLE;
  hnor1.Init.PageSize = FMC_PAGE_SIZE_NONE;
  /* Timing */
  Timing.AddressSetupTime = 9;
  Timing.AddressHoldTime = 15;
  Timing.DataSetupTime = 5;
  Timing.BusTurnAroundDuration = 4;
  Timing.CLKDivision = 16;
  Timing.DataLatency = 17;
  Timing.AccessMode = FMC_ACCESS_MODE_A;
  /* ExtTiming */

  if (HAL_NOR_Init(&hnor1, &Timing, NULL) != HAL_OK)
  {
    Error_Handler( );
  }

  /** Perform the SDRAM1 memory initialization sequence
  */
  hsdram1.Instance = FMC_SDRAM_DEVICE;
  /* hsdram1.Init */
  hsdram1.Init.SDBank = FMC_SDRAM_BANK2;
  hsdram1.Init.ColumnBitsNumber = FMC_SDRAM_COLUMN_BITS_NUM_9;
  hsdram1.Init.RowBitsNumber = FMC_SDRAM_ROW_BITS_NUM_12;
  hsdram1.Init.MemoryDataWidth = FMC_SDRAM_MEM_BUS_WIDTH_32;
  hsdram1.Init.InternalBankNumber = FMC_SDRAM_INTERN_BANKS_NUM_4;
  hsdram1.Init.CASLatency = FMC_SDRAM_CAS_LATENCY_3;
  hsdram1.Init.WriteProtection = FMC_SDRAM_WRITE_PROTECTION_DISABLE;
  hsdram1.Init.SDClockPeriod = FMC_SDRAM_CLOCK_PERIOD_2;
  hsdram1.Init.ReadBurst = FMC_SDRAM_RBURST_ENABLE;
  hsdram1.Init.ReadPipeDelay = FMC_SDRAM_RPIPE_DELAY_0;
  /* SdramTiming */
  SdramTiming.LoadToActiveDelay = 2;
  SdramTiming.ExitSelfRefreshDelay = 7;
  SdramTiming.SelfRefreshTime = 4;
  SdramTiming.RowCycleDelay = 7;
  SdramTiming.WriteRecoveryTime = 4;
  SdramTiming.RPDelay = 2;
  SdramTiming.RCDDelay = 2;

  if (HAL_SDRAM_Init(&hsdram1, &SdramTiming) != HAL_OK)
  {
    Error_Handler( );
  }

  /* USER CODE BEGIN FMC_Init 2 */
  SDRAM_Do_InitializeSequence();
  {
	  volatile uint32_t* dst = (volatile uint32_t *)0xD0000000;
	  for (int i = 0; i < 100; i++)
	  {
		  dst[i] = 0x12345678 + i;
	  }
	  for (int i = 0; i < 100; i++)
	  {
		  if (dst[i] != 0x12345678 + i)
		  {
			  Error_Handler();
			  while(1);
		  }
	  }
  }
  /* USER CODE END FMC_Init 2 */
}

static void MX_GPIO_Init(void)
{
  GPIO_InitTypeDef GPIO_InitStruct = {0};

  /* GPIO Ports Clock Enable */
  __HAL_RCC_GPIOI_CLK_ENABLE();
  __HAL_RCC_GPIOK_CLK_ENABLE();
  __HAL_RCC_GPIOG_CLK_ENABLE();
  __HAL_RCC_GPIOD_CLK_ENABLE();
  __HAL_RCC_GPIOE_CLK_ENABLE();
  __HAL_RCC_GPIOJ_CLK_ENABLE();
  __HAL_RCC_GPIOA_CLK_ENABLE();
  __HAL_RCC_GPIOH_CLK_ENABLE();
  __HAL_RCC_GPIOC_CLK_ENABLE();
  __HAL_RCC_GPIOB_CLK_ENABLE();
  __HAL_RCC_GPIOF_CLK_ENABLE();

  /*Configure GPIO pin Output Level */
  HAL_GPIO_WritePin(LED1_GPIO_Port, LED1_Pin, GPIO_PIN_RESET);

  /*Configure GPIO pin Output Level */
  HAL_GPIO_WritePin(LCD_BL_GPIO_Port, LCD_BL_Pin, GPIO_PIN_RESET);

  /*Configure GPIO pin : LED1_Pin */
  GPIO_InitStruct.Pin = LED1_Pin;
  GPIO_InitStruct.Mode = GPIO_MODE_OUTPUT_PP;
  GPIO_InitStruct.Pull = GPIO_NOPULL;
  GPIO_InitStruct.Speed = GPIO_SPEED_FREQ_LOW;
  HAL_GPIO_Init(LED1_GPIO_Port, &GPIO_InitStruct);

  /*Configure GPIO pin : TOUCH_INT_Pin */
  GPIO_InitStruct.Pin = TOUCH_INT_Pin;
  GPIO_InitStruct.Mode = GPIO_MODE_INPUT;
  GPIO_InitStruct.Pull = GPIO_NOPULL;
  HAL_GPIO_Init(TOUCH_INT_GPIO_Port, &GPIO_InitStruct);

  /*Configure GPIO pin : LCD_BL_Pin */
  GPIO_InitStruct.Pin = LCD_BL_Pin;
  GPIO_InitStruct.Mode = GPIO_MODE_OUTPUT_PP;
  GPIO_InitStruct.Pull = GPIO_NOPULL;
  GPIO_InitStruct.Speed = GPIO_SPEED_FREQ_LOW;
  HAL_GPIO_Init(LCD_BL_GPIO_Port, &GPIO_InitStruct);

}

/* USER CODE BEGIN 4 */

static void MPU_Config(void)
{
  MPU_Region_InitTypeDef MPU_InitStruct;

  /* Disable the MPU */
  HAL_MPU_Disable();

  /* Configure the MPU attributes as WT for SDRAM */
  MPU_InitStruct.Enable = MPU_REGION_ENABLE;
  MPU_InitStruct.BaseAddress = SDRAM_DEVICE_ADDR;
  MPU_InitStruct.Size = MPU_REGION_SIZE_32MB;
  MPU_InitStruct.AccessPermission = MPU_REGION_FULL_ACCESS;
  MPU_InitStruct.IsBufferable = MPU_ACCESS_NOT_BUFFERABLE;
  MPU_InitStruct.IsCacheable = MPU_ACCESS_CACHEABLE;
  MPU_InitStruct.IsShareable = MPU_ACCESS_NOT_SHAREABLE;
  MPU_InitStruct.Number = MPU_REGION_NUMBER0;
  MPU_InitStruct.TypeExtField = MPU_TEX_LEVEL0;
  MPU_InitStruct.SubRegionDisable = 0x00;
  MPU_InitStruct.DisableExec = MPU_INSTRUCTION_ACCESS_ENABLE;

  HAL_MPU_ConfigRegion(&MPU_InitStruct);

  /* Configure the MPU attributes as WT for NOR */
  MPU_InitStruct.Enable = MPU_REGION_ENABLE;
  MPU_InitStruct.BaseAddress = NOR_DEVICE_ADDR;
  MPU_InitStruct.Size = MPU_REGION_SIZE_16MB;
  MPU_InitStruct.AccessPermission = MPU_REGION_FULL_ACCESS;
  MPU_InitStruct.IsBufferable = MPU_ACCESS_NOT_BUFFERABLE;
  MPU_InitStruct.IsCacheable = MPU_ACCESS_CACHEABLE;
  MPU_InitStruct.IsShareable = MPU_ACCESS_NOT_SHAREABLE;
  MPU_InitStruct.Number = MPU_REGION_NUMBER1;
  MPU_InitStruct.TypeExtField = MPU_TEX_LEVEL0;
  MPU_InitStruct.SubRegionDisable = 0x00;
  MPU_InitStruct.DisableExec = MPU_INSTRUCTION_ACCESS_ENABLE;

  HAL_MPU_ConfigRegion(&MPU_InitStruct);

  /* Enable the MPU */
  HAL_MPU_Enable(MPU_PRIVILEGED_DEFAULT);
}

/* USER CODE END 4 */

void Error_Handler(void)
{
  /* USER CODE BEGIN Error_Handler_Debug */
  /* User can add his own implementation to report the HAL error return state */
  //__disable_irq();
  //while (1)
  //{
  //}
  /* USER CODE END Error_Handler_Debug */
}

/************************ (C) COPYRIGHT STMicroelectronics *****END OF FILE****/
